# ATtiny45 device description
Architecture: AVR8; Family: tinyAVR
Registers are 8-bit, access not given, no defined reset value unless marked. A register's access mark holds for its fields unless they carry their own. Offsets are from the block's base; [hi:lo] are bit positions.

## PORTB — I/O Port
Instances: PORTB 0x00
0x36 PINB bits used 5:0 — Input Pins, Port B
0x37 DDRB bits used 5:0 — Data Direction Register, Port B
0x38 PORTB bits used 5:0 — Data Register, Port B

## AC — Analog Comparator
Instances: AC 0x00
0x23 ADCSRB — ADC Control and Status Register B
  [6] ACME — Analog Comparator Multiplexer Enable
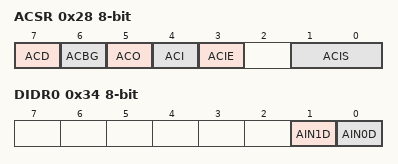
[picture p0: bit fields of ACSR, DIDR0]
0x28 ACSR — Analog Comparator Control And Status Register
  [7] ACD — Analog Comparator Disable
  [6] ACBG — Analog Comparator Bandgap Select
  [5] ACO — Analog Compare Output
  [4] ACI — Analog Comparator Interrupt Flag
  [3] ACIE — Analog Comparator Interrupt Enable
  [1:0] ACIS — Analog Comparator Interrupt Mode Select bits
    0=INTERRUPT_ON_TOGGLE; 2=INTERRUPT_ON_FALLING_EDGE; 3=INTERRUPT_ON_RISING_EDGE
0x34 DIDR0
  [1] AIN1D — AIN1 Digital Input Disable
  [0] AIN0D — AIN0 Digital Input Disable

## ADC — Analog-to-Digital Converter
Instances: ADC 0x00
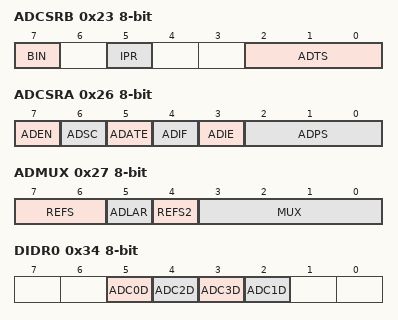
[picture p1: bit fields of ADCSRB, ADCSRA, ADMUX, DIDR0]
0x23 ADCSRB — ADC Control and Status Register B
  [7] BIN — Bipolar Input Mode
  [5] IPR — Input Polarity Mode
  [2:0] ADTS — ADC Auto Trigger Sources
    0=FREE_RUNNING_MODE; 1=ANALOG_COMPARATOR; 2=EXTERNAL_INTERRUPT_REQUEST_0; 3=TIMER_COUNTER0_COMPARE_MATCH_A; 4=TIMER_COUNTER0_OVERFLOW; 5=TIMER_COUNTER1_COMPARE_MATCH_B; 6=TIMER_COUNTER1_OVERFLOW; 7=TIMER_COUNTER1_CAPTURE_EVENT
0x24 ADC 16-bit — ADC Data Register Bytes
0x26 ADCSRA — The ADC Control and Status register
  [7] ADEN — ADC Enable
  [6] ADSC — ADC Start Conversion
  [5] ADATE — ADC Auto Trigger Enable
  [4] ADIF — ADC Interrupt Flag
  [3] ADIE — ADC Interrupt Enable
  [2:0] ADPS — ADC Prescaler Select Bits
    0=2; 1=2; 2=4; 3=8; 4=16; 5=32; 6=64; 7=128
0x27 ADMUX — The ADC multiplexer Selection Register
  [7:6] REFS — Reference Selection Bits
  [5] ADLAR — Left Adjust Result
  [4] REFS2 — Reference Selection Bit 2
  [3:0] MUX — Analog Channel and Gain Selection Bits
0x34 DIDR0 — Digital Input Disable Register 0
  [5] ADC0D — ADC0 Digital input Disable
  [4] ADC2D — ADC2 Digital input Disable
  [3] ADC3D — ADC3 Digital input Disable
  [2] ADC1D — ADC1 Digital input Disable

## USI — Universal Serial Interface
Instances: USI 0x00
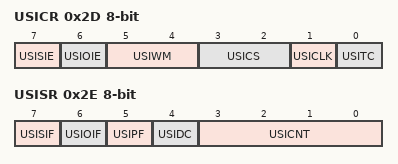
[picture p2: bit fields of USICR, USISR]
0x2D USICR — USI Control Register
  [7] USISIE — Start Condition Interrupt Enable
  [6] USIOIE — Counter Overflow Interrupt Enable
  [5:4] USIWM — USI Wire Mode Bits
    0=NORMAL_OPERATION; 1=THREE_WIRE_MODE; 2=TWO_WIRE_MODE; 3=TWO_WIRE_MODE_HELD_LOW
  [3:2] USICS — USI Clock Source Select Bits
  [1] USICLK — Clock Strobe
  [0] USITC — Toggle Clock Port Pin
0x2E USISR — USI Status Register
  [7] USISIF — Start Condition Interrupt Flag
  [6] USIOIF — Counter Overflow Interrupt Flag
  [5] USIPF — Stop Condition Flag
  [4] USIDC — Data Output Collision
  [3:0] USICNT — USI Counter Value Bits
0x2F USIDR — USI Data Register
0x30 USIBR — USI Buffer Register

## EXINT — External Interrupts
Instances: EXINT 0x00
0x35 PCMSK bits used 5:0 — Pin Change Enable Mask
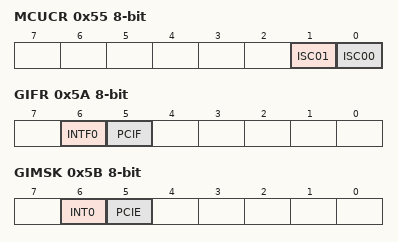
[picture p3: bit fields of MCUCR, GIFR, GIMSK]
0x55 MCUCR — MCU Control Register
  [1] ISC01 — Interrupt Sense Control 0 Bit 1
  [0] ISC00 — Interrupt Sense Control 0 Bit 0
    0=LOW_LEVEL_OF_INTX; 1=ANY_LOGICAL_CHANGE_ON_INTX; 2=FALLING_EDGE_OF_INTX; 3=RISING_EDGE_OF_INTX
0x5A GIFR — General Interrupt Flag register
  [6] INTF0 — External Interrupt Flag 0
  [5] PCIF — Pin Change Interrupt Flag
0x5B GIMSK — General Interrupt Mask Register
  [6] INT0 — External Interrupt Request 0 Enable
  [5] PCIE — Pin Change Interrupt Enable

## EEPROM
Instances: EEPROM 0x00
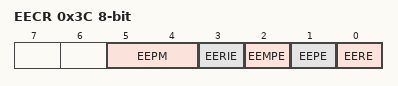
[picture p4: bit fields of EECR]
0x3C EECR — EEPROM Control Register
  [5:4] EEPM — EEPROM Programming Mode Bits
    0=ERASE_AND_WRITE_IN_ONE_OPERATION; 1=ERASE_ONLY; 2=WRITE_ONLY
  [3] EERIE — EEPROM Ready Interrupt Enable
  [2] EEMPE — EEPROM Master Write Enable
  [1] EEPE — EEPROM Write Enable
  [0] EERE — EEPROM Read Enable
0x3D EEDR — EEPROM Data Register
0x3E EEAR 16-bit bits used 8:0 — EEPROM Address Register Bytes
